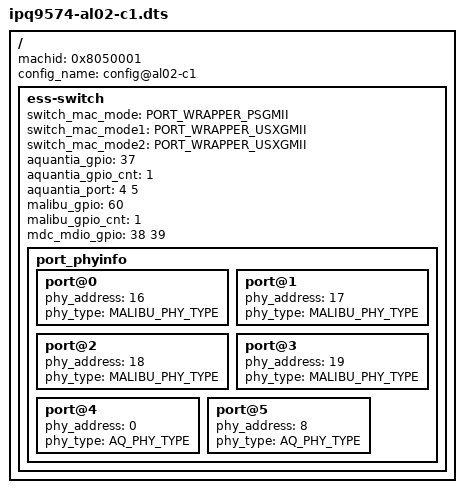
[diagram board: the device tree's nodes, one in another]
/*
 * Copyright (c) 2016-2019, 2021, The Linux Foundation. All rights reserved.
 *
 * This program is free software; you can redistribute it and/or modify
 * it under the terms of the GNU General Public License version 2 and
 * only version 2 as published by the Free Software Foundation.
 *
 * This program is distributed in the hope that it will be useful,
 * but WITHOUT ANY WARRANTY; without even the implied warranty of
 * MERCHANTABILITY or FITNESS FOR A PARTICULAR PURPOSE.  See the
 * GNU General Public License for more details.
 */

/dts-v1/;
#include "ipq9574-soc.dtsi"
/ {
	machid = <0x8050001>;
	config_name = "config@al02-c1";

	ess-switch {
		switch_mac_mode = <PORT_WRAPPER_PSGMII>;
		switch_mac_mode1 = <PORT_WRAPPER_USXGMII>;
		switch_mac_mode2 = <PORT_WRAPPER_USXGMII>;
		aquantia_gpio = <37>;
		aquantia_gpio_cnt = <1>;
		aquantia_port = <4 5>;
		malibu_gpio = <60>;
		malibu_gpio_cnt = <1>;
		mdc_mdio_gpio = <38 39>;
		port_phyinfo {
			port@0 {
				phy_address = <16>;
				phy_type = <MALIBU_PHY_TYPE>;
			};
			port@1 {
				phy_address = <17>;
				phy_type = <MALIBU_PHY_TYPE>;
			};
			port@2 {
				phy_address = <18>;
				phy_type = <MALIBU_PHY_TYPE>;
			};
			port@3 {
				phy_address = <19>;
				phy_type = <MALIBU_PHY_TYPE>;
			};
			port@4 {
				phy_address = <0>;
				phy_type = <AQ_PHY_TYPE>;
			};
			port@5 {
				phy_address = <8>;
				phy_type = <AQ_PHY_TYPE>;
			};
		};
	};
};
